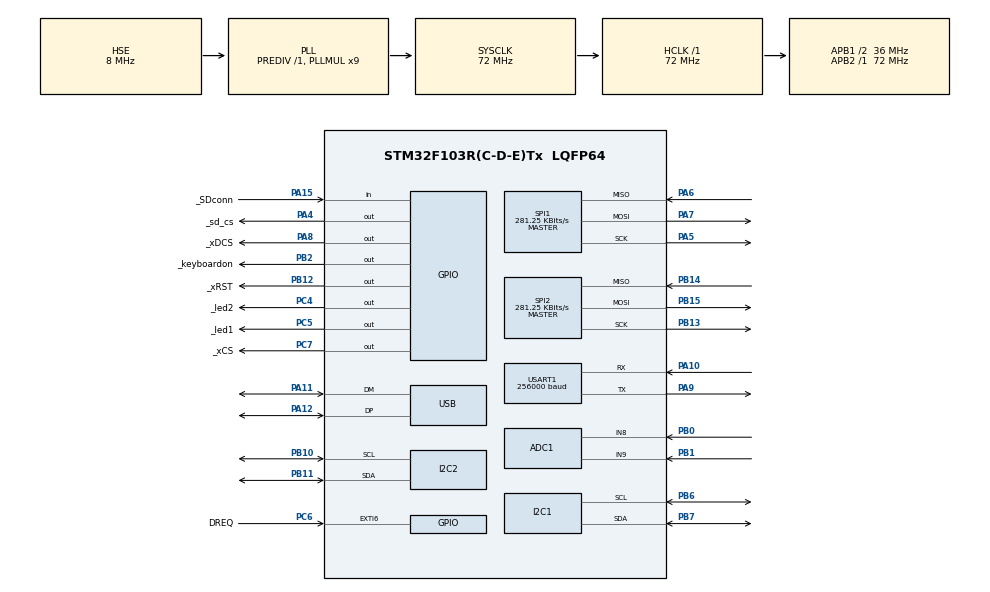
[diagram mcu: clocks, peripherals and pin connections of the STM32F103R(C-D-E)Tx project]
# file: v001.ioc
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ADC1.Channel-18\#ChannelRegularConversion=ADC_CHANNEL_8
ADC1.Channel-19\#ChannelRegularConversion=ADC_CHANNEL_9
ADC1.InjNumberOfConversion=0
ADC1.NbrOfConversion=2
ADC1.NbrOfConversionFlag=1
ADC1.Rank-18\#ChannelRegularConversion=1
ADC1.Rank-19\#ChannelRegularConversion=2
ADC1.SamplingTime-18\#ChannelRegularConversion=ADC_SAMPLETIME_1CYCLE_5
ADC1.SamplingTime-19\#ChannelRegularConversion=ADC_SAMPLETIME_1CYCLE_5
ADC1.master=1
Dma.ADC1.1.Direction=DMA_PERIPH_TO_MEMORY
Dma.ADC1.1.Instance=DMA1_Channel1
Dma.ADC1.1.MemDataAlignment=DMA_MDATAALIGN_HALFWORD
Dma.ADC1.1.MemInc=DMA_MINC_ENABLE
Dma.ADC1.1.Mode=DMA_NORMAL
Dma.ADC1.1.PeriphDataAlignment=DMA_PDATAALIGN_HALFWORD
Dma.ADC1.1.PeriphInc=DMA_PINC_DISABLE
Dma.ADC1.1.Priority=DMA_PRIORITY_VERY_HIGH
Dma.I2C2_TX.0.Direction=DMA_MEMORY_TO_PERIPH
Dma.I2C2_TX.0.Instance=DMA1_Channel4
Dma.I2C2_TX.0.MemDataAlignment=DMA_MDATAALIGN_BYTE
Dma.I2C2_TX.0.MemInc=DMA_MINC_ENABLE
Dma.I2C2_TX.0.Mode=DMA_NORMAL
Dma.I2C2_TX.0.PeriphDataAlignment=DMA_PDATAALIGN_BYTE
Dma.I2C2_TX.0.PeriphInc=DMA_PINC_DISABLE
Dma.I2C2_TX.0.Priority=DMA_PRIORITY_VERY_HIGH
Dma.Request0=I2C2_TX
Dma.Request1=ADC1
FREERTOS.Tasks01=defaultTask,0,1000,StartDefaultTask,Default
FREERTOS.configMINIMAL_STACK_SIZE=500
FREERTOS.configTOTAL_HEAP_SIZE=26000
FREERTOS.configUSE_IDLE_HOOK=1
I2C1.I2C_Mode=I2C_Standard
I2C2.I2C_Mode=I2C_Fast
Mcu.Family=STM32F1
Mcu.Name=STM32F103R(C-D-E)Tx
Mcu.Package=LQFP64
NVIC.DMA1_Channel1_IRQn=true\:5\:0\:false\:false\:true
NVIC.DMA1_Channel4_IRQn=true\:5\:0\:false\:false\:true
NVIC.EXTI9_5_IRQn=true\:5\:0\:false\:false\:true
NVIC.PriorityGroup=NVIC_PRIORITYGROUP_4
NVIC.TIM5_IRQn=true\:0\:0\:false\:false\:true
NVIC.TimeBase=TIM5_IRQn
NVIC.TimeBaseIP=TIM5
PA10.Mode=Asynchronous
PA10.Signal=USART1_RX
PA11.Mode=Device
PA11.Signal=USB_DM
PA12.Mode=Device
PA12.Signal=USB_DP
PA15.GPIO_Label=_SDconn
PA15.Signal=GPIO_Input
PA4.GPIO_Label=_sd_cs
PA4.Signal=GPIO_Output
PA5.Mode=Full_Duplex_Master
PA5.Signal=SPI1_SCK
PA6.Mode=Full_Duplex_Master
PA6.Signal=SPI1_MISO
PA7.Mode=Full_Duplex_Master
PA7.Signal=SPI1_MOSI
PA8.GPIO_Label=_xDCS
PA8.Signal=GPIO_Output
PA9.Mode=Asynchronous
PA9.Signal=USART1_TX
PB0.Signal=ADCx_IN8
PB1.Signal=ADCx_IN9
PB10.Mode=I2C
PB10.Signal=I2C2_SCL
PB11.Mode=I2C
PB11.Signal=I2C2_SDA
PB12.GPIO_Label=_xRST
PB12.Signal=GPIO_Output
PB13.Mode=Full_Duplex_Master
PB13.Signal=SPI2_SCK
PB14.Mode=Full_Duplex_Master
PB14.Signal=SPI2_MISO
PB15.Mode=Full_Duplex_Master
PB15.Signal=SPI2_MOSI
PB2.GPIO_Label=_keyboardon
PB2.Signal=GPIO_Output
PB6.Mode=I2C
PB6.Signal=I2C1_SCL
PB7.Mode=I2C
PB7.Signal=I2C1_SDA
PC14-OSC32_IN.Mode=LSE-External-Oscillator
PC14-OSC32_IN.Signal=RCC_OSC32_IN
PC15-OSC32_OUT.Mode=LSE-External-Oscillator
PC15-OSC32_OUT.Signal=RCC_OSC32_OUT
PC4.GPIO_Label=_led2
PC4.Signal=GPIO_Output
PC5.GPIO_Label=_led1
PC5.Signal=GPIO_Output
PC6.GPIO_Label=DREQ
PC6.GPIO_ModeDefaultEXTI=GPIO_MODE_IT_RISING_FALLING
PC6.GPIO_PuPd=GPIO_PULLDOWN
PC6.Signal=GPXTI6
PC7.GPIO_Label=_xCS
PC7.Signal=GPIO_Output
PD0-OSC_IN.Mode=HSE-External-Oscillator
PD0-OSC_IN.Signal=RCC_OSC_IN
PD1-OSC_OUT.Mode=HSE-External-Oscillator
PD1-OSC_OUT.Signal=RCC_OSC_OUT
ProjectManager.HeapSize=0x7000
ProjectManager.StackSize=0x4000
ProjectManager.TargetToolchain=MDK-ARM V5
RCC.ADCPresc=RCC_ADCPCLK2_DIV6
RCC.AHBFreq_Value=72000000
RCC.APB1CLKDivider=RCC_HCLK_DIV2
RCC.APB1Freq_Value=36000000
RCC.APB1TimFreq_Value=72000000
RCC.APB2Freq_Value=72000000
RCC.APB2TimFreq_Value=72000000
RCC.HCLKFreq_Value=72000000
RCC.HSIState=RCC_HSI_ON
RCC.PLLMUL=RCC_PLL_MUL9
RCC.PLLSourceVirtual=RCC_PLLSOURCE_HSE
RCC.RTCClockSelection=RCC_RTCCLKSOURCE_LSE
RCC.SYSCLKFreq_VALUE=72000000
RCC.SYSCLKSource=RCC_SYSCLKSOURCE_PLLCLK
RCC.USBFreq_Value=48000000
RCC.USBPrescaler=RCC_USBCLKSOURCE_PLL_DIV1_5
SH.ADCx_IN8.0=ADC1_IN8,IN8
SH.ADCx_IN9.0=ADC1_IN9,IN9
SPI1.BaudRatePrescaler=SPI_BAUDRATEPRESCALER_256
SPI1.CalculateBaudRate=281.25 KBits/s
SPI1.Mode=SPI_MODE_MASTER
SPI2.BaudRatePrescaler=SPI_BAUDRATEPRESCALER_128
SPI2.CalculateBaudRate=281.25 KBits/s
SPI2.Mode=SPI_MODE_MASTER
USART1.BaudRate=256000
VP_FREERTOS_VS_ENABLE.Mode=Enabled
VP_RTC_No_RTC_Output.Mode=RTC_OUT_NO
VP_SYS_VS_tim5.Mode=TIM5
board=v001

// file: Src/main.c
/**
  ******************************************************************************
  * File Name          : main.c
  * Description        : Main program body
  ******************************************************************************
  *
  * COPYRIGHT(c) 2016 STMicroelectronics
  *
  * Redistribution and use in source and binary forms, with or without modification,
  * are permitted provided that the following conditions are met:
  *   1. Redistributions of source code must retain the above copyright notice,
  *      this list of conditions and the following disclaimer.
  *   2. Redistributions in binary form must reproduce the above copyright notice,
  *      this list of conditions and the following disclaimer in the documentation
  *      and/or other materials provided with the distribution.
  *   3. Neither the name of STMicroelectronics nor the names of its contributors
  *      may be used to endorse or promote products derived from this software
  *      without specific prior written permission.
  *
  * THIS SOFTWARE IS PROVIDED BY THE COPYRIGHT HOLDERS AND CONTRIBUTORS "AS IS"
  * AND ANY EXPRESS OR IMPLIED WARRANTIES, INCLUDING, BUT NOT LIMITED TO, THE
  * IMPLIED WARRANTIES OF MERCHANTABILITY AND FITNESS FOR A PARTICULAR PURPOSE ARE
  * DISCLAIMED. IN NO EVENT SHALL THE COPYRIGHT HOLDER OR CONTRIBUTORS BE LIABLE
  * FOR ANY DIRECT, INDIRECT, INCIDENTAL, SPECIAL, EXEMPLARY, OR CONSEQUENTIAL
  * DAMAGES (INCLUDING, BUT NOT LIMITED TO, PROCUREMENT OF SUBSTITUTE GOODS OR
  * SERVICES; LOSS OF USE, DATA, OR PROFITS; OR BUSINESS INTERRUPTION) HOWEVER
  * CAUSED AND ON ANY THEORY OF LIABILITY, WHETHER IN CONTRACT, STRICT LIABILITY,
  * OR TORT (INCLUDING NEGLIGENCE OR OTHERWISE) ARISING IN ANY WAY OUT OF THE USE
  * OF THIS SOFTWARE, EVEN IF ADVISED OF THE POSSIBILITY OF SUCH DAMAGE.
  *
  ******************************************************************************
  */
#include "stm32f1xx_hal.h"
#include "cmsis_os.h"
#include "adc.h"
#include "dma.h"
#include "i2c.h"
#include "rtc.h"
#include "spi.h"
#include "usart.h"
#include "usb.h"
#include "gpio.h"

/* USER CODE BEGIN Includes */
#include "system.h"
/* USER CODE END Includes */

/* USER CODE BEGIN PV */
/* Private variables ---------------------------------------------------------*/

/* USER CODE END PV */

void SystemClock_Config(void);
void MX_FREERTOS_Init(void);

/* USER CODE BEGIN PFP */
/* Private function prototypes -----------------------------------------------*/

/* USER CODE END PFP */

int main(void)
{

  /* MCU Configuration----------------------------------------------------------*/

  /* Reset of all peripherals, Initializes the Flash interface and the Systick. */
  HAL_Init();

  /* Configure the system clock */
  SystemClock_Config();

  /* Initialize all configured peripherals */
  MX_GPIO_Init();
  MX_DMA_Init();
  MX_ADC1_Init();
  MX_I2C1_Init();
  MX_I2C2_Init();
  MX_SPI1_Init();
  MX_SPI2_Init();
  MX_USART1_UART_Init();
  MX_RTC_Init();
  MX_USB_PCD_Init();

  /* USER CODE BEGIN 2 */
	//MX_FREERTOS_Init();
  sys_init();
	/* USER CODE END 2 */

  /* Call init function for freertos objects (in freertos.c) */
  MX_FREERTOS_Init();

  /* Start scheduler */
  osKernelStart();

  /* We should never get here as control is now taken by the scheduler */

  /* Infinite loop */
  while (1)
  {

  }

}

/** System Clock Configuration
*/
void SystemClock_Config(void)
{

  RCC_OscInitTypeDef RCC_OscInitStruct;
  RCC_ClkInitTypeDef RCC_ClkInitStruct;
  RCC_PeriphCLKInitTypeDef PeriphClkInit;

  RCC_OscInitStruct.OscillatorType = RCC_OSCILLATORTYPE_HSE|RCC_OSCILLATORTYPE_LSE;
  RCC_OscInitStruct.HSEState = RCC_HSE_ON;
  RCC_OscInitStruct.HSEPredivValue = RCC_HSE_PREDIV_DIV1;
  RCC_OscInitStruct.LSEState = RCC_LSE_ON;
  RCC_OscInitStruct.PLL.PLLState = RCC_PLL_ON;
  RCC_OscInitStruct.PLL.PLLSource = RCC_PLLSOURCE_HSE;
  RCC_OscInitStruct.PLL.PLLMUL = RCC_PLL_MUL9;
  HAL_RCC_OscConfig(&RCC_OscInitStruct);

  RCC_ClkInitStruct.ClockType = RCC_CLOCKTYPE_HCLK|RCC_CLOCKTYPE_SYSCLK
                              |RCC_CLOCKTYPE_PCLK1|RCC_CLOCKTYPE_PCLK2;
  RCC_ClkInitStruct.SYSCLKSource = RCC_SYSCLKSOURCE_PLLCLK;
  RCC_ClkInitStruct.AHBCLKDivider = RCC_SYSCLK_DIV1;
  RCC_ClkInitStruct.APB1CLKDivider = RCC_HCLK_DIV2;
  RCC_ClkInitStruct.APB2CLKDivider = RCC_HCLK_DIV1;
  HAL_RCC_ClockConfig(&RCC_ClkInitStruct, FLASH_LATENCY_2);

  PeriphClkInit.PeriphClockSelection = RCC_PERIPHCLK_RTC|RCC_PERIPHCLK_ADC
                              |RCC_PERIPHCLK_USB;
  PeriphClkInit.RTCClockSelection = RCC_RTCCLKSOURCE_LSE;
  PeriphClkInit.AdcClockSelection = RCC_ADCPCLK2_DIV6;
  PeriphClkInit.UsbClockSelection = RCC_USBCLKSOURCE_PLL_DIV1_5;
  HAL_RCCEx_PeriphCLKConfig(&PeriphClkInit);

  HAL_SYSTICK_Config(HAL_RCC_GetHCLKFreq()/1000);

  HAL_SYSTICK_CLKSourceConfig(SYSTICK_CLKSOURCE_HCLK);

  /* SysTick_IRQn interrupt configuration */
  HAL_NVIC_SetPriority(SysTick_IRQn, 15, 0);
}

/************************ (C) COPYRIGHT STMicroelectronics *****END OF FILE****/

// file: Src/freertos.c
/**
  ******************************************************************************
  * File Name          : freertos.c
  * Description        : Code for freertos applications
  ******************************************************************************
  *
  * COPYRIGHT(c) 2016 STMicroelectronics
  *
  * Redistribution and use in source and binary forms, with or without modification,
  * are permitted provided that the following conditions are met:
  *   1. Redistributions of source code must retain the above copyright notice,
  *      this list of conditions and the following disclaimer.
  *   2. Redistributions in binary form must reproduce the above copyright notice,
  *      this list of conditions and the following disclaimer in the documentation
  *      and/or other materials provided with the distribution.
  *   3. Neither the name of STMicroelectronics nor the names of its contributors
  *      may be used to endorse or promote products derived from this software
  *      without specific prior written permission.
  *
  * THIS SOFTWARE IS PROVIDED BY THE COPYRIGHT HOLDERS AND CONTRIBUTORS "AS IS"
  * AND ANY EXPRESS OR IMPLIED WARRANTIES, INCLUDING, BUT NOT LIMITED TO, THE
  * IMPLIED WARRANTIES OF MERCHANTABILITY AND FITNESS FOR A PARTICULAR PURPOSE ARE
  * DISCLAIMED. IN NO EVENT SHALL THE COPYRIGHT HOLDER OR CONTRIBUTORS BE LIABLE
  * FOR ANY DIRECT, INDIRECT, INCIDENTAL, SPECIAL, EXEMPLARY, OR CONSEQUENTIAL
  * DAMAGES (INCLUDING, BUT NOT LIMITED TO, PROCUREMENT OF SUBSTITUTE GOODS OR
  * SERVICES; LOSS OF USE, DATA, OR PROFITS; OR BUSINESS INTERRUPTION) HOWEVER
  * CAUSED AND ON ANY THEORY OF LIABILITY, WHETHER IN CONTRACT, STRICT LIABILITY,
  * OR TORT (INCLUDING NEGLIGENCE OR OTHERWISE) ARISING IN ANY WAY OUT OF THE USE
  * OF THIS SOFTWARE, EVEN IF ADVISED OF THE POSSIBILITY OF SUCH DAMAGE.
  *
  ******************************************************************************
  */

#include "FreeRTOS.h"
#include "task.h"
#include "cmsis_os.h"

osThreadId defaultTaskHandle;

void StartDefaultTask(void const * argument);

void MX_FREERTOS_Init(void); /* (MISRA C 2004 rule 8.1) */

/* Hook prototypes */

/* Init FreeRTOS */

void MX_FREERTOS_Init(void) {

  /* Create the thread(s) */
  /* definition and creation of defaultTask */
  osThreadDef(defaultTask, StartDefaultTask, osPriorityNormal, 0, 1000);
  defaultTaskHandle = osThreadCreate(osThread(defaultTask), NULL);

}

/* StartDefaultTask function */
void StartDefaultTask(void const * argument)
{

  /* USER CODE BEGIN StartDefaultTask */
  /* Infinite loop */
  for(;;)
  {
    osDelay(10000);
  }
  /* USER CODE END StartDefaultTask */
}

/************************ (C) COPYRIGHT STMicroelectronics *****END OF FILE****/
